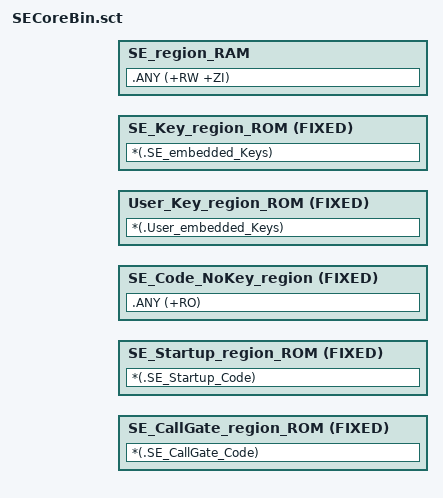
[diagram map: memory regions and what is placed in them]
#! armclang --target=arm-arm-none-eabi  -mcpu=cortex-m0plus -E -xc
; *************************************************************
; *** Scatter-Loading Description File generated by uVision ***
; *************************************************************
#include "..\..\Linker_Common\MDK-ARM\mapping_sbsfu.h"
#include "..\..\Linker_Common\MDK-ARM\mapping_fwimg.h"


; *** regions needed by SE_CoreBin project ***
LR_SE SE_CODE_REGION_ROM_START {
  SE_CallGate_region_ROM SE_CALLGATE_REGION_ROM_START FIXED SE_CALLGATE_REGION_ROM_SIZE {
  *(.SE_CallGate_Code)
  }
  SE_Startup_region_ROM SE_STARTUP_REGION_ROM_START FIXED  {
  *(.SE_Startup_Code)
  }
  SE_Code_NoKey_region SE_CODE_NOKEY_REGION_ROM_START FIXED SE_CODE_NOKEY_REGION_ROM_SIZE{
  .ANY (+RO)
  }
  User_Key_region_ROM USER_KEY_REGION_ROM_START FIXED USER_KEY_REGION_ROM_SIZE {
  *(.User_embedded_Keys)
  }
  SE_Key_region_ROM SE_KEY_REGION_ROM_START FIXED SE_KEY_REGION_ROM_SIZE {
  *(.SE_embedded_Keys)
  }
  SE_region_RAM SE_REGION_RAM_STACK_TOP SE_RAM_REGION_SIZE  {
  .ANY (+RW +ZI)
  }
}
